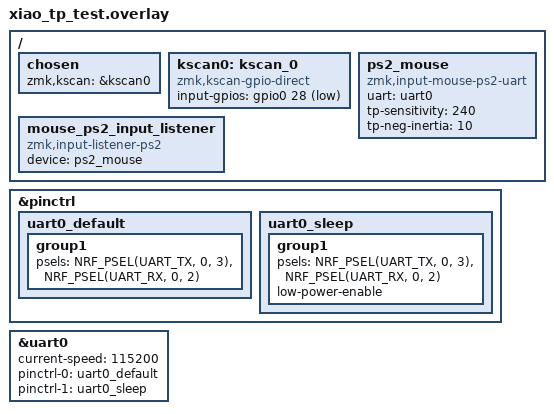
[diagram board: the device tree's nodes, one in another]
/* xiao_tp_test.overlay */
#include <dt-bindings/zmk/matrix_transform.h>
#include <dt-bindings/pinctrl/nrf-pinctrl.h>

/ {
    chosen {
        zmk,kscan = &kscan0;
    };

    kscan0: kscan_0 {
        compatible = "zmk,kscan-gpio-direct";
        input-gpios = <&gpio0 28 (GPIO_ACTIVE_LOW | GPIO_PULL_UP)>;
    };

    /* ↓ ラベル "ps2_mouse:" を追加 */
    ps2_mouse: ps2_mouse {
        compatible = "zmk,input-mouse-ps2-uart";
        status = "okay";
        uart = <&uart0>;
        tp-sensitivity = <240>;
        tp-neg-inertia = <10>;
    };

    /* ↓ このリスナー設定が不足していました */
    mouse_ps2_input_listener {
        compatible = "zmk,input-listener-ps2";
        status = "okay";
        device = <&ps2_mouse>;
    };
};

&pinctrl {
    uart0_default: uart0_default {
        group1 {
            psels = <NRF_PSEL(UART_TX, 0, 3)>, <NRF_PSEL(UART_RX, 0, 2)>;
        };
    };

    uart0_sleep: uart0_sleep {
        group1 {
            psels = <NRF_PSEL(UART_TX, 0, 3)>, <NRF_PSEL(UART_RX, 0, 2)>;
            low-power-enable;
        };
    };
};

&uart0 {
    status = "okay";
    current-speed = <115200>;
    pinctrl-0 = <&uart0_default>;
    pinctrl-1 = <&uart0_sleep>;
    pinctrl-names = "default", "sleep";
};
